# SS_Ctrl_reg_array: IP-XACT component
VLNV tuni.fi:ip:SS_Ctrl_reg_array:1.1

## Parameters
IOCELL_COUNT = 28 — update/propagate this value to match cell numbers
IOCELL_CFG_W = 5
AW = 32
DW = 32
SS_CTRL_W = 31 — configurable: 2 <= N <= 31
NUM_SS = 4

## Bus interfaces (logical=physical port)
Clock: target tuni.fi:interface:clock:1.0
  clk=clk
Reset: target tuni.fi:interface:reset:1.0
  reset=reset_n
obi_target: target tuni.fi:interface:OBI:1.0, memory map sysctrl_ctrl_reg_array
  req=req_i, addr=addr_i, we=we_i, wdata=wdata_i, gnt=gnt_o, rdata=rdata_o, be=be_i, gntpar=gntpar_o, rvalid=rvalid_o, rready=rready_i, rvalidpar=rvalidpar_o
icn_ss_ctrl: initiator tuni.fi:interface:SS_Ctrl:1.0
  clk_ctrl=ss_ctrl_icn
io_cfg: initiator tuni.fi:interface:io_cell_cfg:1.0
  cfg=cell_cfg
rst_icn: initiator tuni.fi:interface:reset:1.0
  reset=reset_icn
rst_ss: initiator tuni.fi:interface:reset:1.0
  reset=reset_ss
ss_ctrl_0: initiator tuni.fi:interface:SS_Ctrl:1.0
  clk_ctrl=ss_ctrl_0, irq_en=irq_en_0
ss_ctrl_1: initiator tuni.fi:interface:SS_Ctrl:1.0
  clk_ctrl=ss_ctrl_1, irq_en=irq_en_1
ss_ctrl_2: initiator tuni.fi:interface:SS_Ctrl:1.0
  clk_ctrl=ss_ctrl_2, irq_en=irq_en_2
ss_ctrl_3: initiator tuni.fi:interface:SS_Ctrl:1.0
  clk_ctrl=ss_ctrl_3, irq_en=irq_en_3
pmod_sel: initiator tuni.fi:interface:GPIO:1.0
  gpo=pmod_sel
fetch_en: initiator tuni.fi:interface:GPIO:1.0
  gpo=fetch_en
ss_ctrl_4: initiator tuni.fi:interface:SS_Ctrl:1.0
  clk_ctrl=ss_ctrl_4, irq_en=irq_en_4

## Ports
out ss_ctrl_icn[SS_CTRL_W-1:0]
out cell_cfg[IOCELL_CFG_W*IOCELL_COUNT-1:0]
out reset_icn
out ss_ctrl_{n}[SS_CTRL_W-1:0] (n=0..4)
out irq_en_{n} (n=0..4)
in clk
out pmod_sel[7:0]
out fetch_en[3:0]
out rvalid_o
out rvalidpar_o
out gnt_o
out gntpar_o
in reset_n
in rready_i
out rdata_o[DW-1:0]
in addr_i[AW-1:0]
in be_i[DW/8-1:0]
in req_i
in wdata_i[DW-1:0]
in we_i
out reset_ss[NUM_SS-1:0]

## Address spaces and blocks
sysctrl_ctrl_reg_array.registerBlock: base 'h0, range 'h200, width 32

## Registers
Registers are 32-bit, access not given, reset 0x0 unless marked. A register's access mark holds for its fields unless they carry their own. Offsets are from the block's base; lines under a group give offsets from that group; [hi:lo] are bit positions; {n}, {i} and the like mark numbered series; 'fields as' and 'values as' point back to an identical list; <NAME> marks a mode.

## sysctrl_ctrl_reg_array.registerBlock — * IO cells cfg registers are 32 bits but only connected for IOCELL_CFG_W number of bits. Rest are reserved for updates. * SS control registers are 32 bits but only connected for SS_CTRL_W number of bits. 31th bit is IRQ en. 0th bit is global clock control. 1st bit is high speed clock control. Rest are reserverd.
Base 0x00000000
0x00 fetch_en rw reset not defined — fetch enable register
  [1:0] fetch_en_reg — controls instruction fetch of Ibex RISC-V core
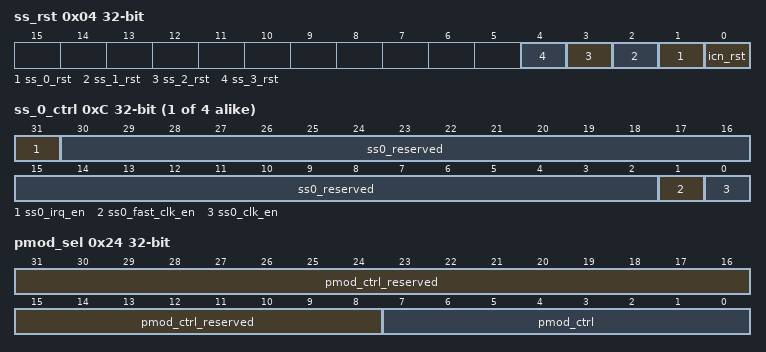
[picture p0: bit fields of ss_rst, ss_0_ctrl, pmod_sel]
0x04 ss_rst — register for ss resets
  [n+1] ss_{n}_rst (n=0..3), [0] icn_rst
0x08 icn_ss_ctrl — ICN SS control
  [31:0] icn_ctrl — Connected to ICN SS with width of SS_CTRL_W. Currently not used in ICN.
{0xC+4i} ss_{i}_ctrl (i=0..3) — SS {i} control
  [31] ss{i}_irq_en, [30:2] ss{i}_reserved, [1] ss{i}_fast_clk_en, [0] ss{i}_clk_en
0x1C ss_4_ctrl — SS 4 control
0x20 ss_ctrl_reserved_1 — reserved addr for additional ss
0x24 pmod_sel (reset mask 0xFF) — pmod host control
  [31:8] pmod_ctrl_reserved, [7:0] pmod_ctrl
0x28 io_cell_cfg_0 — uart io cell cfg
  [31:0] cell_cfg
0x2C io_cell_cfg_1 — uart io cell cfg
  [31:0] cell_cfg
{0x28+4i} io_cell_cfg_{i} (i=2..8) — spi io cell cfg
  [31:0] cell_cfg
0x4C io_cell_cfg_9 reset not defined — gpio cfg
  [31:0] cell_cfg
0x50 io_cell_cfg_10 reset not defined — gpio cfg
  [31:0] cell_cfg
0x54 io_cell_cfg_11 — gpio cfg
  [31:0] cell_cfg
0x58 io_cell_cfg_12 — gpio cfg
  [31:0] cell_cfg
0x5C io_cell_cfg_13 reset not defined — gpio cfg
  [31:0] cell_cfg
{0x28+4i} io_cell_cfg_{i} (i=14..16) — gpio cfg
  [31:0] cell_cfg
{0x28+4i} io_cell_cfg_{i} reset not defined (i=17..24) — gpio cfg
  [31:0] gpio_cfg
0x100 boot_reg_0 rw reset 0x6F — Idle loop boot reg
  [31:0] boot_idle
0x104 boot_reg_1 rw reset 0x6F — Idle loop boot reg to prevent fetch illagal instr while at boot reg 0
  [31:0] boot_fetch
0x180 return_reg_0 rw reset 0x6F — Idle loop return reg after main
  [31:0] post_main_idle
0x184 return_reg_1 rw reset 0x6F — Idle loop return reg to prevent fetch illagal instr while at return reg 0
  [31:0] post_main_fetch
